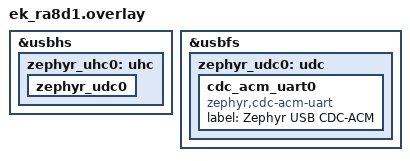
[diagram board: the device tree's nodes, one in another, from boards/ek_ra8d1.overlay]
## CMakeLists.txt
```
# Copyright (c) 2022 Nordic Semiconductor ASA
# SPDX-License-Identifier: Apache-2.0

cmake_minimum_required(VERSION 3.28.0)
find_package(Zephyr REQUIRED HINTS $ENV{ZEPHYR_BASE})
project(usb-shell)

FILE(GLOB app_sources src/*.c)
target_sources(app PRIVATE ${app_sources})
```

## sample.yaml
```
sample:
  name: USB support shell sample
tests:
  sample.usbd.shell:
    depends_on:
      - usbd
    tags:
      - usb
    extra_args:
      - FILE_SUFFIX=device
    integration_platforms:
      - nrf52840dk/nrf52840
      - nrf54h20dk/nrf54h20/cpuapp
      - frdm_k64f
      - mimxrt685_evk/mimxrt685s/cm33
      - mimxrt1060_evk/mimxrt1062/qspi
    harness: keyboard
  sample.usbh.shell:
    depends_on:
      - usbh
    tags:
      - usb
    extra_args:
      - FILE_SUFFIX=host
    platform_allow:
      - rd_rw612_bga
    build_only: true
  sample.usbh.shell.shield:
    depends_on:
      - usbd
    tags:
      - usb
      - shield
    extra_args:
      - FILE_SUFFIX=device_and_host
      - SHIELD="sparkfun_max3421e"
    platform_allow:
      - nrf52840dk/nrf52840
      - frdm_k64f
    build_only: true
  sample.usbh.shell.virtual:
    tags:
      - usb
    extra_args:
      - FILE_SUFFIX=device_and_host
      - EXTRA_DTC_OVERLAY_FILE="virtual.overlay"
    platform_allow:
      - native_sim/native/64
    build_only: true
```

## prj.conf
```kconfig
CONFIG_SHELL=y
CONFIG_USB_DEVICE_STACK_NEXT=y
CONFIG_USBD_SHELL=y
CONFIG_USBD_LOOPBACK_CLASS=y
CONFIG_UDC_BUF_POOL_SIZE=4096

CONFIG_LOG=y
CONFIG_USBD_LOG_LEVEL_WRN=y
CONFIG_UDC_DRIVER_LOG_LEVEL_WRN=y
```

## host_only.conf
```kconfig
CONFIG_SHELL=y
CONFIG_USB_HOST_STACK=y
CONFIG_USBH_SHELL=y

CONFIG_LOG=y
CONFIG_USBH_LOG_LEVEL_WRN=y
CONFIG_UHC_DRIVER_LOG_LEVEL_WRN=y
```

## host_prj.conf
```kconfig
CONFIG_LOG=y
CONFIG_SHELL=y
CONFIG_UHC_DRIVER_LOG_LEVEL_WRN=y
CONFIG_USBH_LOG_LEVEL_WRN=y
CONFIG_USBH_SHELL=y
CONFIG_USB_HOST_STACK=y
CONFIG_USB_DEVICE_STACK_NEXT=n
```

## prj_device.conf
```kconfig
CONFIG_SHELL=y
CONFIG_USB_DEVICE_STACK_NEXT=y
CONFIG_CDC_ACM_SERIAL_INITIALIZE_AT_BOOT=n
CONFIG_USBD_SHELL=y
CONFIG_USBD_LOOPBACK_CLASS=y
CONFIG_USBD_BUF_POOL_SIZE=4096

CONFIG_LOG=y
CONFIG_USBD_LOG_LEVEL_WRN=y
CONFIG_UDC_DRIVER_LOG_LEVEL_WRN=y
```

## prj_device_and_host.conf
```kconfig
CONFIG_SHELL=y
CONFIG_USB_DEVICE_STACK_NEXT=y
CONFIG_USBD_SHELL=y

CONFIG_USB_HOST_STACK=y
CONFIG_USBH_SHELL=y

CONFIG_LOG=y
CONFIG_USBD_LOG_LEVEL_WRN=y
CONFIG_USBH_LOG_LEVEL_WRN=y
CONFIG_UDC_DRIVER_LOG_LEVEL_WRN=y
CONFIG_UHC_DRIVER_LOG_LEVEL_WRN=y
```

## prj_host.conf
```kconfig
CONFIG_SHELL=y

CONFIG_USB_HOST_STACK=y
CONFIG_USBH_SHELL=y
CONFIG_USBH_HUB_CLASS=y

CONFIG_LOG=y
CONFIG_USBH_LOG_LEVEL_WRN=y
CONFIG_UHC_DRIVER_LOG_LEVEL_WRN=y
```

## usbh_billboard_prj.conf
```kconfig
CONFIG_SHELL=y

CONFIG_USB_HOST_STACK=y
CONFIG_USBH_SHELL=y

CONFIG_LOG=y
CONFIG_USBH_LOG_LEVEL_WRN=y
CONFIG_UHC_DRIVER_LOG_LEVEL_WRN=y

CONFIG_USBH_BILLBOARD_CLASS=y
CONFIG_USBH_BILLBOARD_LOG_LEVEL_DBG=y
```

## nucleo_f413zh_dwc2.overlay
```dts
/*
 * Copyright (c) 2023 Nordic Semiconductor ASA
 *
 * SPDX-License-Identifier: Apache-2.0
 */

/delete-node/ &zephyr_udc0;

/ {
	soc {
		dwc2_fsotg0: usb@50000000 {
			compatible = "st,stm32f4-fsotg", "snps,dwc2";
			reg = <0x50000000 0x40000>;
			interrupts = <67 0>;
			interrupt-names = "fsotg";
			clocks = <&rcc STM32_CLOCK_BUS_AHB2 0x00000080>,
				 <&rcc STM32_SRC_PLL_Q NO_SEL>;
			num-out-eps = <6>;
			num-in-eps = <6>;
			ghwcfg1 = <0x00000000>;
			ghwcfg2 = <0x229ed520>;
			ghwcfg4 = <0x17f08030>;
		};
	};
};

zephyr_udc0: &dwc2_fsotg0 {
	pinctrl-0 = <&usb_otg_fs_dm_pa11 &usb_otg_fs_dp_pa12>;
	pinctrl-names = "default";
	status = "okay";
};
```

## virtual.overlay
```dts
/*
 * Copyright (c) 2022 Nordic Semiconductor ASA
 *
 * SPDX-License-Identifier: Apache-2.0
 */

/delete-node/ &zephyr_udc0;

/ {
	zephyr_uhc0: uhc_vrt0 {
		compatible = "zephyr,uhc-virtual";

		zephyr_udc0: udc_vrt0 {
			compatible = "zephyr,udc-virtual";
			num-bidir-endpoints = <8>;
			maximum-speed = "high-speed";
		};

		udc1: udc_vrt1 {
			compatible = "zephyr,udc-virtual";
			num-bidir-endpoints = <8>;
			maximum-speed = "full-speed";
		};
	};
};
```

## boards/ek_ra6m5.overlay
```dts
/*
 * Copyright (c) 2024 Renesas Electronics Corporation
 *
 * SPDX-License-Identifier: Apache-2.0
 */

&zephyr_udc0 {
	status = "okay";

	cdc_acm_uart0 {
		compatible = "zephyr,cdc-acm-uart";
		label = "Zephyr USB CDC-ACM";
	};
};
```

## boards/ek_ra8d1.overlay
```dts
/*
 * Copyright (c) 2024 Renesas Electronics Corporation
 *
 * SPDX-License-Identifier: Apache-2.0
 */

/delete-node/ &zephyr_udc0;

&usbhs {
	status = "okay";

	zephyr_uhc0: uhc {
		status = "okay";
		zephyr_udc0 {};
	};
};

&usbfs {
	status = "okay";

	zephyr_udc0: udc {
		status = "okay";

		cdc_acm_uart0 {
			compatible = "zephyr,cdc-acm-uart";
			label = "Zephyr USB CDC-ACM";
		};
	};
};
```

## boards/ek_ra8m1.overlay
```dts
/*
 * Copyright (c) 2024 Renesas Electronics Corporation
 *
 * SPDX-License-Identifier: Apache-2.0
 */

/delete-node/ &zephyr_udc0;

&usbhs {
	status = "okay";

	zephyr_uhc0: uhc {
		status = "okay";
	};
};

&usbfs {
	status = "okay";

	zephyr_udc0: udc {
		status = "okay";
	};
};
```

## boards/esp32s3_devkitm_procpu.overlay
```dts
/*
 * Copyright (c) 2023 Nordic Semiconductor ASA
 *
 * SPDX-License-Identifier: Apache-2.0
 */

zephyr_uhc0: &usb_otg {
	status = "okay";
};
```

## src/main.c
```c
/*
 * Copyright (c) 2022 Nordic Semiconductor ASA
 *
 * SPDX-License-Identifier: Apache-2.0
 */

#include <zephyr/kernel.h>
#include <zephyr/usb/usbh.h>

#if CONFIG_USB_HOST_STACK
USBH_CONTROLLER_DEFINE(sample_uhs_ctx, DEVICE_DT_GET(DT_NODELABEL(zephyr_uhc0)));
#endif

int main(void)
{
	return 0;
}
```
